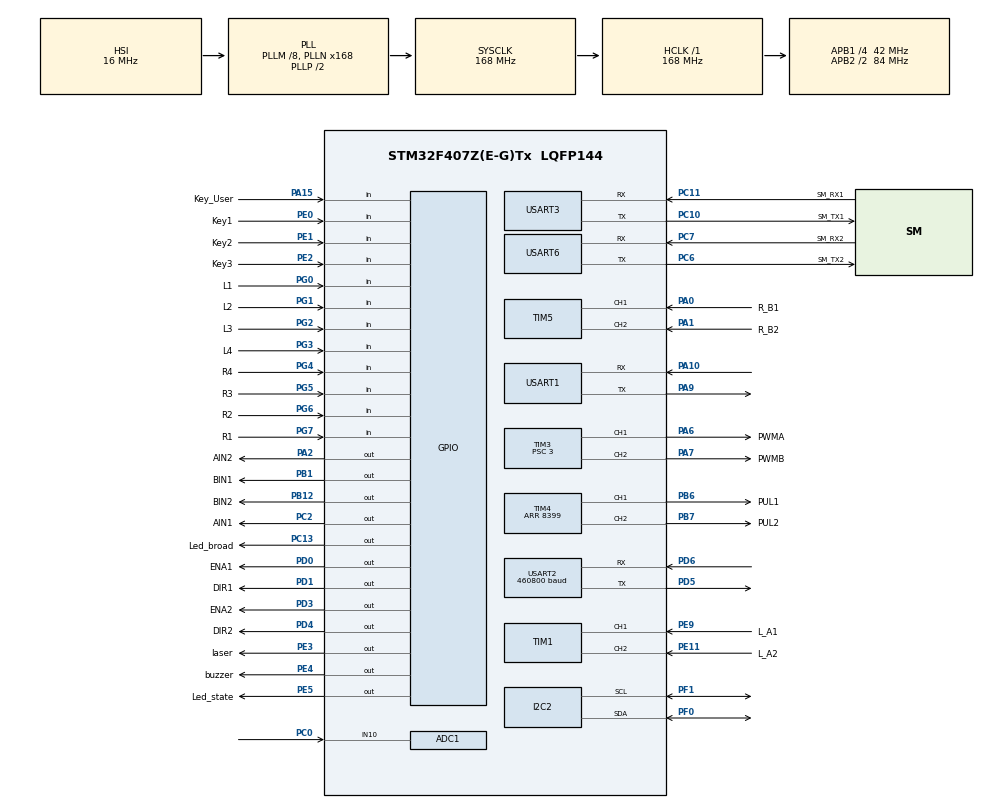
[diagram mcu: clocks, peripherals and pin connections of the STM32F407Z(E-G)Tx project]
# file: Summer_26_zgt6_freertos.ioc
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ADC1.Channel-1\#ChannelRegularConversion=ADC_CHANNEL_10
ADC1.NbrOfConversionFlag=1
ADC1.Rank-1\#ChannelRegularConversion=1
ADC1.SamplingTime-1\#ChannelRegularConversion=ADC_SAMPLETIME_480CYCLES
ADC1.master=1
Dma.Request0=USART1_RX
Dma.Request1=USART1_TX
Dma.Request2=USART2_RX
Dma.Request3=USART3_RX
Dma.Request4=USART3_TX
Dma.Request5=USART6_RX
Dma.Request6=USART6_TX
Dma.USART1_RX.0.Direction=DMA_PERIPH_TO_MEMORY
Dma.USART1_RX.0.FIFOMode=DMA_FIFOMODE_DISABLE
Dma.USART1_RX.0.Instance=DMA2_Stream2
Dma.USART1_RX.0.MemDataAlignment=DMA_MDATAALIGN_BYTE
Dma.USART1_RX.0.MemInc=DMA_MINC_ENABLE
Dma.USART1_RX.0.Mode=DMA_CIRCULAR
Dma.USART1_RX.0.PeriphDataAlignment=DMA_PDATAALIGN_BYTE
Dma.USART1_RX.0.PeriphInc=DMA_PINC_DISABLE
Dma.USART1_RX.0.Priority=DMA_PRIORITY_LOW
Dma.USART1_TX.1.Direction=DMA_MEMORY_TO_PERIPH
Dma.USART1_TX.1.FIFOMode=DMA_FIFOMODE_DISABLE
Dma.USART1_TX.1.Instance=DMA2_Stream7
Dma.USART1_TX.1.MemDataAlignment=DMA_MDATAALIGN_BYTE
Dma.USART1_TX.1.MemInc=DMA_MINC_ENABLE
Dma.USART1_TX.1.Mode=DMA_NORMAL
Dma.USART1_TX.1.PeriphDataAlignment=DMA_PDATAALIGN_BYTE
Dma.USART1_TX.1.PeriphInc=DMA_PINC_DISABLE
Dma.USART1_TX.1.Priority=DMA_PRIORITY_LOW
Dma.USART2_RX.2.Direction=DMA_PERIPH_TO_MEMORY
Dma.USART2_RX.2.FIFOMode=DMA_FIFOMODE_DISABLE
Dma.USART2_RX.2.Instance=DMA1_Stream5
Dma.USART2_RX.2.MemDataAlignment=DMA_MDATAALIGN_BYTE
Dma.USART2_RX.2.MemInc=DMA_MINC_ENABLE
Dma.USART2_RX.2.Mode=DMA_NORMAL
Dma.USART2_RX.2.PeriphDataAlignment=DMA_PDATAALIGN_BYTE
Dma.USART2_RX.2.PeriphInc=DMA_PINC_DISABLE
Dma.USART2_RX.2.Priority=DMA_PRIORITY_LOW
Dma.USART3_RX.3.Direction=DMA_PERIPH_TO_MEMORY
Dma.USART3_RX.3.FIFOMode=DMA_FIFOMODE_DISABLE
Dma.USART3_RX.3.Instance=DMA1_Stream1
Dma.USART3_RX.3.MemDataAlignment=DMA_MDATAALIGN_BYTE
Dma.USART3_RX.3.MemInc=DMA_MINC_ENABLE
Dma.USART3_RX.3.Mode=DMA_CIRCULAR
Dma.USART3_RX.3.PeriphDataAlignment=DMA_PDATAALIGN_BYTE
Dma.USART3_RX.3.PeriphInc=DMA_PINC_DISABLE
Dma.USART3_RX.3.Priority=DMA_PRIORITY_MEDIUM
Dma.USART3_TX.4.Direction=DMA_MEMORY_TO_PERIPH
Dma.USART3_TX.4.FIFOMode=DMA_FIFOMODE_DISABLE
Dma.USART3_TX.4.Instance=DMA1_Stream3
Dma.USART3_TX.4.MemDataAlignment=DMA_MDATAALIGN_BYTE
Dma.USART3_TX.4.MemInc=DMA_MINC_ENABLE
Dma.USART3_TX.4.Mode=DMA_NORMAL
Dma.USART3_TX.4.PeriphDataAlignment=DMA_PDATAALIGN_BYTE
Dma.USART3_TX.4.PeriphInc=DMA_PINC_DISABLE
Dma.USART3_TX.4.Priority=DMA_PRIORITY_MEDIUM
Dma.USART6_RX.5.Direction=DMA_PERIPH_TO_MEMORY
Dma.USART6_RX.5.FIFOMode=DMA_FIFOMODE_DISABLE
Dma.USART6_RX.5.Instance=DMA2_Stream1
Dma.USART6_RX.5.MemDataAlignment=DMA_MDATAALIGN_BYTE
Dma.USART6_RX.5.MemInc=DMA_MINC_ENABLE
Dma.USART6_RX.5.Mode=DMA_CIRCULAR
Dma.USART6_RX.5.PeriphDataAlignment=DMA_PDATAALIGN_BYTE
Dma.USART6_RX.5.PeriphInc=DMA_PINC_DISABLE
Dma.USART6_RX.5.Priority=DMA_PRIORITY_MEDIUM
Dma.USART6_TX.6.Direction=DMA_MEMORY_TO_PERIPH
Dma.USART6_TX.6.FIFOMode=DMA_FIFOMODE_DISABLE
Dma.USART6_TX.6.Instance=DMA2_Stream6
Dma.USART6_TX.6.MemDataAlignment=DMA_MDATAALIGN_BYTE
Dma.USART6_TX.6.MemInc=DMA_MINC_ENABLE
Dma.USART6_TX.6.Mode=DMA_NORMAL
Dma.USART6_TX.6.PeriphDataAlignment=DMA_PDATAALIGN_BYTE
Dma.USART6_TX.6.PeriphInc=DMA_PINC_DISABLE
Dma.USART6_TX.6.Priority=DMA_PRIORITY_MEDIUM
FREERTOS.BinarySemaphores01=Sem_Init,Dynamic,NULL,Depleted
FREERTOS.Mutexes01=PcMutex,Dynamic,NULL,Available
FREERTOS.Tasks01=uiTask,24,128,StartuiTask,As weak,NULL,Dynamic,NULL,NULL;InitTask,55,256,StartInitTask,As external,NULL,Dynamic,NULL,NULL;GimbalTask,50,1024,StartGimbalTask,As external,NULL,Dynamic,NULL,NULL;DebugTask,8,256,StartDebugTask,As external,NULL,Dynamic,NULL,NULL;ChassisTask,48,512,StartChassisTask,As external,NULL,Dynamic,NULL,NULL;inputTask,48,128,StartinputTask,As external,NULL,Dynamic,NULL,NULL
FREERTOS.configGENERATE_RUN_TIME_STATS=0
FREERTOS.configRECORD_STACK_HIGH_ADDRESS=1
Mcu.Family=STM32F4
Mcu.Name=STM32F407Z(E-G)Tx
Mcu.Package=LQFP144
NVIC.DMA1_Stream1_IRQn=true\:5\:0\:false\:false\:true\:true\:false\:true\:true
NVIC.DMA1_Stream3_IRQn=true\:5\:0\:false\:false\:true\:true\:false\:true\:true
NVIC.DMA1_Stream5_IRQn=true\:5\:0\:false\:false\:true\:true\:false\:true\:true
NVIC.DMA2_Stream1_IRQn=true\:5\:0\:false\:false\:true\:true\:false\:true\:true
NVIC.DMA2_Stream2_IRQn=true\:5\:0\:false\:false\:true\:true\:false\:true\:true
NVIC.DMA2_Stream6_IRQn=true\:5\:0\:false\:false\:true\:true\:false\:true\:true
NVIC.DMA2_Stream7_IRQn=true\:5\:0\:false\:false\:true\:true\:false\:true\:true
NVIC.I2C2_ER_IRQn=true\:5\:0\:false\:false\:true\:true\:true\:true\:true
NVIC.I2C2_EV_IRQn=true\:5\:0\:false\:false\:true\:true\:true\:true\:true
NVIC.PriorityGroup=NVIC_PRIORITYGROUP_4
NVIC.TIM6_DAC_IRQn=true\:15\:0\:false\:false\:true\:false\:false\:true\:true
NVIC.TimeBase=TIM6_DAC_IRQn
NVIC.TimeBaseIP=TIM6
NVIC.USART1_IRQn=true\:5\:0\:false\:false\:true\:true\:true\:true\:true
NVIC.USART2_IRQn=true\:5\:0\:false\:false\:true\:true\:true\:true\:true
NVIC.USART3_IRQn=true\:5\:0\:false\:false\:true\:true\:true\:true\:true
NVIC.USART6_IRQn=true\:5\:0\:false\:false\:true\:true\:true\:true\:true
PA0-WKUP.GPIO_Label=R_B1
PA0-WKUP.GPIO_PuPd=GPIO_PULLUP
PA0-WKUP.Signal=S_TIM5_CH1
PA1.GPIO_Label=R_B2
PA1.GPIO_PuPd=GPIO_PULLUP
PA1.Signal=S_TIM5_CH2
PA10.Mode=Asynchronous
PA10.Signal=USART1_RX
PA13.Mode=Serial_Wire
PA13.Signal=SYS_JTMS-SWDIO
PA14.Mode=Serial_Wire
PA14.Signal=SYS_JTCK-SWCLK
PA15.GPIO_Label=Key_User
PA15.GPIO_PuPd=GPIO_PULLUP
PA15.Signal=GPIO_Input
PA2.GPIO_Label=AIN2
PA2.Signal=GPIO_Output
PA6.GPIO_Label=PWMA
PA6.Signal=S_TIM3_CH1
PA7.GPIO_Label=PWMB
PA7.Signal=S_TIM3_CH2
PA9.Mode=Asynchronous
PA9.Signal=USART1_TX
PB1.GPIO_Label=BIN1
PB1.PinState=GPIO_PIN_SET
PB1.Signal=GPIO_Output
PB12.GPIO_Label=BIN2
PB12.Signal=GPIO_Output
PB6.GPIO_Label=PUL1
PB6.Signal=S_TIM4_CH1
PB7.GPIO_Label=PUL2
PB7.Signal=S_TIM4_CH2
PC0.Signal=ADCx_IN10
PC10.GPIO_Label=SM_TX1
PC10.Mode=Asynchronous
PC10.Signal=USART3_TX
PC11.GPIO_Label=SM_RX1
PC11.Mode=Asynchronous
PC11.Signal=USART3_RX
PC13-ANTI_TAMP.GPIO_Label=Led_broad
PC13-ANTI_TAMP.Signal=GPIO_Output
PC2.GPIO_Label=AIN1
PC2.PinState=GPIO_PIN_SET
PC2.Signal=GPIO_Output
PC6.GPIO_Label=SM_TX2
PC6.Mode=Asynchronous
PC6.Signal=USART6_TX
PC7.GPIO_Label=SM_RX2
PC7.Mode=Asynchronous
PC7.Signal=USART6_RX
PD0.GPIO_Label=ENA1
PD0.PinState=GPIO_PIN_SET
PD0.Signal=GPIO_Output
PD1.GPIO_Label=DIR1
PD1.PinState=GPIO_PIN_SET
PD1.Signal=GPIO_Output
PD3.GPIO_Label=ENA2
PD3.PinState=GPIO_PIN_SET
PD3.Signal=GPIO_Output
PD4.GPIO_Label=DIR2
PD4.PinState=GPIO_PIN_SET
PD4.Signal=GPIO_Output
PD5.Mode=Asynchronous
PD5.Signal=USART2_TX
PD6.Mode=Asynchronous
PD6.Signal=USART2_RX
PE0.GPIO_Label=Key1
PE0.GPIO_PuPd=GPIO_PULLUP
PE0.Signal=GPIO_Input
PE1.GPIO_Label=Key2
PE1.GPIO_PuPd=GPIO_PULLUP
PE1.Signal=GPIO_Input
PE11.GPIO_Label=L_A2
PE11.GPIO_PuPd=GPIO_PULLUP
PE11.Signal=S_TIM1_CH2
PE2.GPIO_Label=Key3
PE2.GPIO_PuPd=GPIO_PULLUP
PE2.Signal=GPIO_Input
PE3.GPIO_Label=laser
PE3.Signal=GPIO_Output
PE4.GPIO_Label=buzzer
PE4.Signal=GPIO_Output
PE5.GPIO_Label=Led_state
PE5.Signal=GPIO_Output
PE9.GPIO_Label=L_A1
PE9.GPIO_PuPd=GPIO_PULLUP
PE9.Signal=S_TIM1_CH1
PF0.Mode=I2C
PF0.Signal=I2C2_SDA
PF1.Mode=I2C
PF1.Signal=I2C2_SCL
PG0.GPIO_Label=L1
PG0.Signal=GPIO_Input
PG1.GPIO_Label=L2
PG1.Signal=GPIO_Input
PG2.GPIO_Label=L3
PG2.Signal=GPIO_Input
PG3.GPIO_Label=L4
PG3.Signal=GPIO_Input
PG4.GPIO_Label=R4
PG4.Signal=GPIO_Input
PG5.GPIO_Label=R3
PG5.Signal=GPIO_Input
PG6.GPIO_Label=R2
PG6.Signal=GPIO_Input
PG7.GPIO_Label=R1
PG7.Signal=GPIO_Input
PH0-OSC_IN.Mode=HSE-External-Oscillator
PH0-OSC_IN.Signal=RCC_OSC_IN
PH1-OSC_OUT.Mode=HSE-External-Oscillator
PH1-OSC_OUT.Signal=RCC_OSC_OUT
ProjectManager.HeapSize=0x200
ProjectManager.StackSize=0x400
ProjectManager.TargetToolchain=CMake
RCC.48MHZClocksFreq_Value=84000000
RCC.AHBFreq_Value=168000000
RCC.APB1CLKDivider=RCC_HCLK_DIV4
RCC.APB1Freq_Value=42000000
RCC.APB1TimFreq_Value=84000000
RCC.APB2CLKDivider=RCC_HCLK_DIV2
RCC.APB2Freq_Value=84000000
RCC.APB2TimFreq_Value=168000000
RCC.CortexFreq_Value=168000000
RCC.HCLKFreq_Value=168000000
RCC.HSE_VALUE=8000000
RCC.HSI_VALUE=16000000
RCC.LSE_VALUE=32768
RCC.PLLM=8
RCC.PLLN=168
RCC.SYSCLKFreq_VALUE=168000000
RCC.SYSCLKSource=RCC_SYSCLKSOURCE_PLLCLK
RCC.VCOOutputFreq_Value=336000000
SH.ADCx_IN10.0=ADC1_IN10,IN10
SH.S_TIM1_CH1.0=TIM1_CH1,Encoder_Interface
SH.S_TIM1_CH2.0=TIM1_CH2,Encoder_Interface
SH.S_TIM3_CH1.0=TIM3_CH1,PWM Generation1 CH1
SH.S_TIM3_CH2.0=TIM3_CH2,PWM Generation2 CH2
SH.S_TIM4_CH1.0=TIM4_CH1,PWM Generation1 CH1
SH.S_TIM4_CH2.0=TIM4_CH2,PWM Generation2 CH2
SH.S_TIM5_CH1.0=TIM5_CH1,Encoder_Interface
SH.S_TIM5_CH2.0=TIM5_CH2,Encoder_Interface
TIM1.EncoderMode=TIM_ENCODERMODE_TI12
TIM3.AutoReloadPreload=TIM_AUTORELOAD_PRELOAD_ENABLE
TIM3.Channel-PWM\ Generation1\ CH1=TIM_CHANNEL_1
TIM3.Channel-PWM\ Generation2\ CH2=TIM_CHANNEL_2
TIM3.Period=999
TIM3.Prescaler=3
TIM4.Channel-PWM\ Generation1\ CH1=TIM_CHANNEL_1
TIM4.Channel-PWM\ Generation2\ CH2=TIM_CHANNEL_2
TIM4.Period=8399
TIM5.EncoderMode=TIM_ENCODERMODE_TI12
USART1.VirtualMode=VM_ASYNC
USART2.BaudRate=460800
USART2.VirtualMode=VM_ASYNC
USART3.VirtualMode=VM_ASYNC
USART6.VirtualMode=VM_ASYNC
VP_FREERTOS_VS_CMSIS_V2.Mode=CMSIS_V2
VP_SYS_VS_tim6.Mode=TIM6
VP_TIM3_VS_ClockSourceINT.Mode=Internal
VP_TIM4_VS_ClockSourceINT.Mode=Internal
board=custom

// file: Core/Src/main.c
/* USER CODE BEGIN Header */
/**
  ******************************************************************************
  * @file           : main.c
  * @brief          : Main program body
  ******************************************************************************
  * @attention
  *
  * Copyright (c) 2026 STMicroelectronics.
  * All rights reserved.
  *
  * This software is licensed under terms that can be found in the LICENSE file
  * in the root directory of this software component.
  * If no LICENSE file comes with this software, it is provided AS-IS.
  *
  ******************************************************************************
  */
/* USER CODE END Header */
#include "main.h"
#include "cmsis_os.h"
#include "adc.h"
#include "dma.h"
#include "i2c.h"
#include "tim.h"
#include "usart.h"
#include "gpio.h"

void SystemClock_Config(void);
void MX_FREERTOS_Init(void);

int main(void)
{

  /* MCU Configuration--------------------------------------------------------*/

  /* Reset of all peripherals, Initializes the Flash interface and the Systick. */
  HAL_Init();

  /* Configure the system clock */
  SystemClock_Config();

  /* Initialize all configured peripherals */
  MX_GPIO_Init();
  MX_DMA_Init();
  MX_USART3_UART_Init();
  MX_ADC1_Init();
  MX_TIM4_Init();
  MX_TIM1_Init();
  MX_TIM3_Init();
  MX_TIM5_Init();
  MX_USART1_UART_Init();
  MX_USART2_UART_Init();
  MX_USART6_UART_Init();
  MX_I2C2_Init();

  /* Init scheduler */
  osKernelInitialize();  /* Call init function for freertos objects (in cmsis_os2.c) */
  MX_FREERTOS_Init();

  /* Start scheduler */
  osKernelStart();

  /* We should never get here as control is now taken by the scheduler */

  /* Infinite loop */
  while (1)
  {

  }
}

void SystemClock_Config(void)
{
  RCC_OscInitTypeDef RCC_OscInitStruct = {0};
  RCC_ClkInitTypeDef RCC_ClkInitStruct = {0};

  /** Configure the main internal regulator output voltage
  */
  __HAL_RCC_PWR_CLK_ENABLE();
  __HAL_PWR_VOLTAGESCALING_CONFIG(PWR_REGULATOR_VOLTAGE_SCALE1);

  /** Initializes the RCC Oscillators according to the specified parameters
  * in the RCC_OscInitTypeDef structure.
  */
  RCC_OscInitStruct.OscillatorType = RCC_OSCILLATORTYPE_HSI;
  RCC_OscInitStruct.HSIState = RCC_HSI_ON;
  RCC_OscInitStruct.HSICalibrationValue = RCC_HSICALIBRATION_DEFAULT;
  RCC_OscInitStruct.PLL.PLLState = RCC_PLL_ON;
  RCC_OscInitStruct.PLL.PLLSource = RCC_PLLSOURCE_HSI;
  RCC_OscInitStruct.PLL.PLLM = 8;
  RCC_OscInitStruct.PLL.PLLN = 168;
  RCC_OscInitStruct.PLL.PLLP = RCC_PLLP_DIV2;
  RCC_OscInitStruct.PLL.PLLQ = 4;
  if (HAL_RCC_OscConfig(&RCC_OscInitStruct) != HAL_OK)
  {
    Error_Handler();
  }

  /** Initializes the CPU, AHB and APB buses clocks
  */
  RCC_ClkInitStruct.ClockType = RCC_CLOCKTYPE_HCLK|RCC_CLOCKTYPE_SYSCLK
                              |RCC_CLOCKTYPE_PCLK1|RCC_CLOCKTYPE_PCLK2;
  RCC_ClkInitStruct.SYSCLKSource = RCC_SYSCLKSOURCE_PLLCLK;
  RCC_ClkInitStruct.AHBCLKDivider = RCC_SYSCLK_DIV1;
  RCC_ClkInitStruct.APB1CLKDivider = RCC_HCLK_DIV4;
  RCC_ClkInitStruct.APB2CLKDivider = RCC_HCLK_DIV2;

  if (HAL_RCC_ClockConfig(&RCC_ClkInitStruct, FLASH_LATENCY_5) != HAL_OK)
  {
    Error_Handler();
  }
}

void HAL_TIM_PeriodElapsedCallback(TIM_HandleTypeDef *htim)
{
  if (htim->Instance == TIM6)
  {
    HAL_IncTick();
  }
}

void Error_Handler(void)
{
  __disable_irq();
  while (1)
  {
  }
}

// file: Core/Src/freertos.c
/* USER CODE BEGIN Header */
/**
  ******************************************************************************
  * File Name          : freertos.c
  * Description        : Code for freertos applications
  ******************************************************************************
  * @attention
  *
  * Copyright (c) 2026 STMicroelectronics.
  * All rights reserved.
  *
  * This software is licensed under terms that can be found in the LICENSE file
  * in the root directory of this software component.
  * If no LICENSE file comes with this software, it is provided AS-IS.
  *
  ******************************************************************************
  */
/* USER CODE END Header */

#include "FreeRTOS.h"
#include "task.h"
#include "main.h"
#include "cmsis_os.h"

/* USER CODE BEGIN Includes */
/* 引入初始化门控接口：默认任务启动后先等待 InitTask 完成全局初始化。 */
#include "task_init.h"
#include "task_gimbal.h"
#include "task_debug.h"
#include "task_input.h"
#include "task_ui.h"

/* USER CODE END Includes */

/* Definitions for uiTask */
osThreadId_t uiTaskHandle;
const osThreadAttr_t uiTask_attributes = {
  .name = "uiTask",
  .stack_size = 128 * 4,
  .priority = (osPriority_t) osPriorityNormal,
};
/* Definitions for InitTask */
osThreadId_t InitTaskHandle;
const osThreadAttr_t InitTask_attributes = {
  .name = "InitTask",
  .stack_size = 256 * 4,
  .priority = (osPriority_t) osPriorityRealtime7,
};
/* Definitions for GimbalTask */
osThreadId_t GimbalTaskHandle;
const osThreadAttr_t GimbalTask_attributes = {
  .name = "GimbalTask",
  .stack_size = 1024 * 4,
  .priority = (osPriority_t) osPriorityRealtime2,
};
/* Definitions for DebugTask */
osThreadId_t DebugTaskHandle;
const osThreadAttr_t DebugTask_attributes = {
  .name = "DebugTask",
  .stack_size = 256 * 4,
  .priority = (osPriority_t) osPriorityLow,
};
/* Definitions for ChassisTask */
osThreadId_t ChassisTaskHandle;
const osThreadAttr_t ChassisTask_attributes = {
  .name = "ChassisTask",
  .stack_size = 512 * 4,
  .priority = (osPriority_t) osPriorityRealtime,
};
/* Definitions for inputTask */
osThreadId_t inputTaskHandle;
const osThreadAttr_t inputTask_attributes = {
  .name = "inputTask",
  .stack_size = 128 * 4,
  .priority = (osPriority_t) osPriorityRealtime,
};
/* Definitions for PcMutex */
osMutexId_t PcMutexHandle;
const osMutexAttr_t PcMutex_attributes = {
  .name = "PcMutex"
};
/* Definitions for Sem_Init */
osSemaphoreId_t Sem_InitHandle;
const osSemaphoreAttr_t Sem_Init_attributes = {
  .name = "Sem_Init"
};

void StartUiTask(void *argument);
extern void StartInitTask(void *argument);
extern void StartGimbalTask(void *argument);
extern void StartDebugTask(void *argument);
extern void StartChassisTask(void *argument);
extern void StartInputTask(void *argument);

void MX_FREERTOS_Init(void); /* (MISRA C 2004 rule 8.1) */

void MX_FREERTOS_Init(void) {
  /* Create the mutex(es) */
  /* creation of PcMutex */
  PcMutexHandle = osMutexNew(&PcMutex_attributes);

  /* Create the semaphores(s) */
  /* creation of Sem_Init */
  Sem_InitHandle = osSemaphoreNew(1, 0, &Sem_Init_attributes);

  /* Create the thread(s) */
  /* creation of uiTask */
  uiTaskHandle = osThreadNew(StartUiTask, NULL, &uiTask_attributes);

  /* creation of InitTask */
  InitTaskHandle = osThreadNew(StartInitTask, NULL, &InitTask_attributes);

  /* creation of GimbalTask */
  GimbalTaskHandle = osThreadNew(StartGimbalTask, NULL, &GimbalTask_attributes);

  /* creation of DebugTask */
  DebugTaskHandle = osThreadNew(StartDebugTask, NULL, &DebugTask_attributes);

  /* creation of ChassisTask */
  ChassisTaskHandle = osThreadNew(StartChassisTask, NULL, &ChassisTask_attributes);

  /* creation of inputTask */
  inputTaskHandle = osThreadNew(StartInputTask, NULL, &inputTask_attributes);

}

__weak void StartUiTask(void *argument)
{
  for(;;)
  {
    osDelay(1);
  }
}
